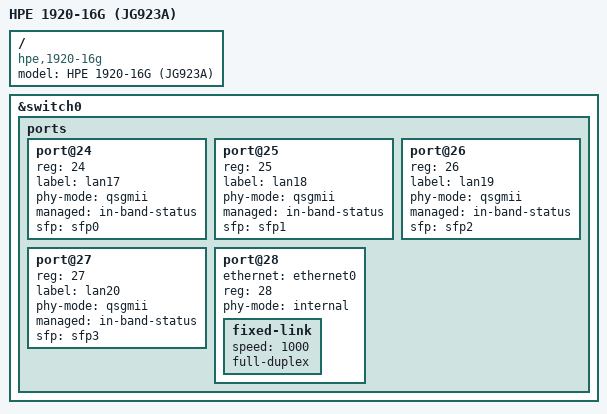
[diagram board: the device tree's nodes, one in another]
// SPDX-License-Identifier: GPL-2.0-or-later OR MIT

#include "rtl8382_hpe_1920.dtsi"

/ {
	compatible = "hpe,1920-16g", "realtek,rtl838x-soc";
	model = "HPE 1920-16G (JG923A)";
};

&switch0 {
	ports {
		#address-cells = <1>;
		#size-cells = <0>;

		SWITCH_PORT(8, 1, internal)
		SWITCH_PORT(9, 2, internal)
		SWITCH_PORT(10, 3, internal)
		SWITCH_PORT(11, 4, internal)
		SWITCH_PORT(12, 5, internal)
		SWITCH_PORT(13, 6, internal)
		SWITCH_PORT(14, 7, internal)
		SWITCH_PORT(15, 8, internal)

		SWITCH_PORT(16, 9, qsgmii)
		SWITCH_PORT(17, 10, qsgmii)
		SWITCH_PORT(18, 11, qsgmii)
		SWITCH_PORT(19, 12, qsgmii)
		SWITCH_PORT(20, 13, qsgmii)
		SWITCH_PORT(21, 14, qsgmii)
		SWITCH_PORT(22, 15, qsgmii)
		SWITCH_PORT(23, 16, qsgmii)

		port@24 {
			reg = <24>;
			label = "lan17";
			phy-mode = "qsgmii";
			//phy-handle = <&phy24>;
			managed = "in-band-status";
			sfp = <&sfp0>;
		};

		port@25 {
			reg = <25>;
			label = "lan18";
			phy-mode = "qsgmii";
			//phy-handle = <&phy25>;
			managed = "in-band-status";
			sfp = <&sfp1>;
		};

		port@26 {
			reg = <26>;
			label = "lan19";
			phy-mode = "qsgmii";
			//phy-handle = <&phy26>;
			managed = "in-band-status";
			sfp = <&sfp2>;
		};

		port@27 {
			reg = <27>;
			label = "lan20";
			phy-mode = "qsgmii";
			//phy-handle = <&phy27>;
			managed = "in-band-status";
			sfp = <&sfp3>;
		};

		port@28 {
			ethernet = <&ethernet0>;
			reg = <28>;
			phy-mode = "internal";
			fixed-link {
				speed = <1000>;
				full-duplex;
			};
		};
	};
};
